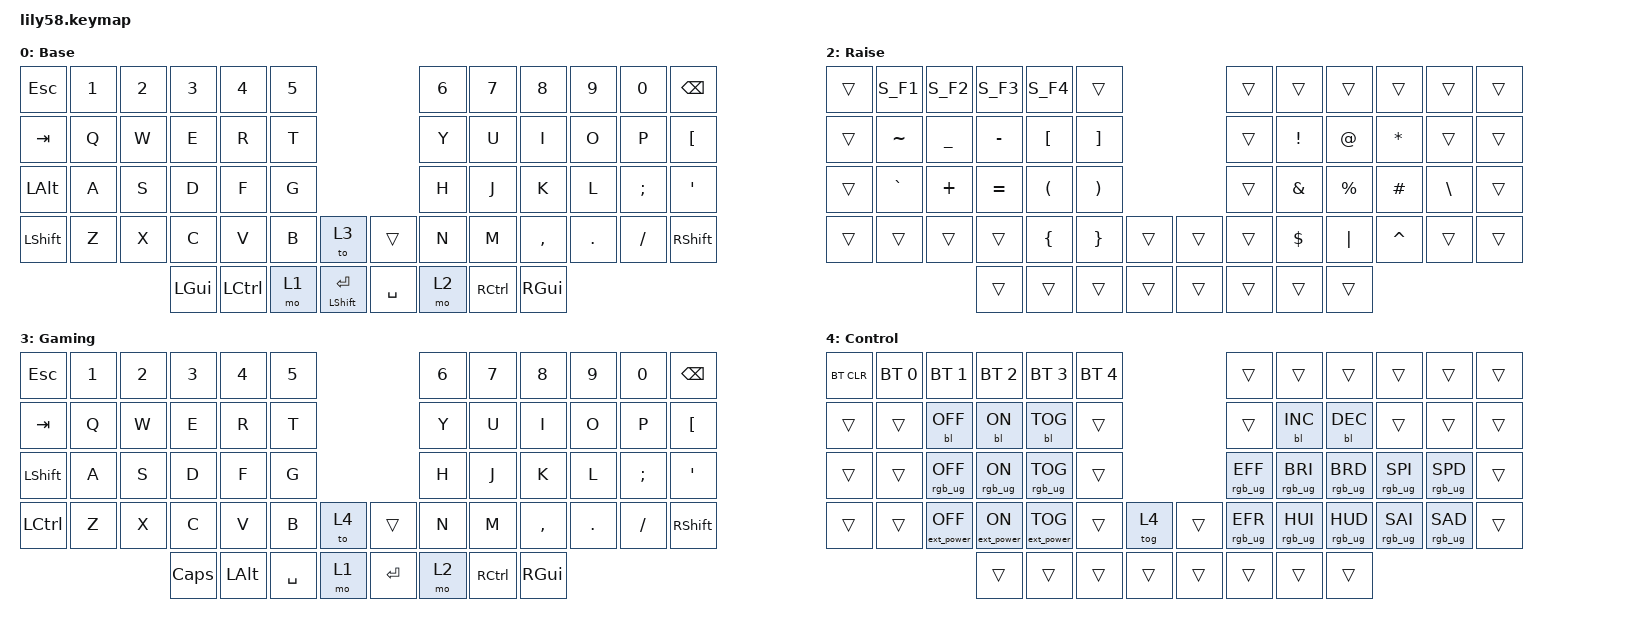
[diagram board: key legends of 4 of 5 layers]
/*
 * Copyright (c) 2020 The ZMK Contributors
 *
 * SPDX-License-Identifier: MIT
 */

#include <behaviors.dtsi>
#include <dt-bindings/zmk/backlight.h>
#include <dt-bindings/zmk/bt.h>
#include <dt-bindings/zmk/ext_power.h>
#include <dt-bindings/zmk/keys.h>
#include <dt-bindings/zmk/rgb.h>
#include <dt-bindings/led/led.h>

&led_strip {
    chain-length = <35>;
};

/ {
    macros {
        S_F1: S_F1 {
            compatible = "zmk,behavior-macro";
            #binding-cells = <0>;
            bindings = <&kt LSHFT &kp F1 &kt LSHFT>;
            label = "S_F1";
        };

        S_F2: S_F2 {
            compatible = "zmk,behavior-macro";
            #binding-cells = <0>;
            bindings = <&kt LSHFT &kp F2 &kt LSHFT>;
            label = "S_F2";
        };

        S_F3: S_F3 {
            compatible = "zmk,behavior-macro";
            #binding-cells = <0>;
            bindings = <&kt LSHFT &kp F3 &kt LSHFT>;
            label = "S_F3";
        };

        S_F4: S_F4 {
            compatible = "zmk,behavior-macro";
            #binding-cells = <0>;
            bindings = <&kt LSHFT &kp F4 &kt LSHFT>;
            label = "S_F4";
        };
    };

    keymap {
        compatible = "zmk,keymap";

        default_layer {
            display-name = "Base";

            // ---------------------------------------------------------------------------------------------------------------
            // |  ESC  |  1  |  2  |  3   |  4   |  5   |                      |  6   |  7    |  8    |  9   |   0   |  BACK |
            // |  TAB  |  Q  |  W  |  E   |  R   |  T   |                      |  Y   |  U    |  I    |  O   |   P   |   [   |
            // |  LALT |  A  |  S  |  D   |  F   |  G   |                      |  H   |  J    |  K    |  L   |   ;   |   '   |
            // | SHIFT |  Z  |  X  |  C   |  V   |  B   |  TOG_3  |  | POW_TOG |  N   |  M    |  ,    |  .   |   /   | SHIFT |
            //        | GUI  | CTRL  | BACK/LOWER |  ENTER/SHIFT  |  | SPACE   | ESC/RAISE | CTRL  | GUI   |

            bindings = <
&kp ESC    &kp N1  &kp N2  &kp N3    &kp N4     &kp N5                                   &kp N6   &kp N7     &kp N8     &kp N9   &kp N0    &kp BACKSPACE
&kp TAB    &kp Q   &kp W   &kp E     &kp R      &kp T                                    &kp Y    &kp U      &kp I      &kp O    &kp P     &kp LEFT_BRACKET
&kp LALT   &kp A   &kp S   &kp D     &kp F      &kp G                                    &kp H    &kp J      &kp K      &kp L    &kp SEMI  &kp SQT
&kp LSHFT  &kp Z   &kp X   &kp C     &kp V      &kp B     &to 3              &trans      &kp N    &kp M      &kp COMMA  &kp DOT  &kp FSLH  &kp RSHFT
                           &kp LGUI  &kp LCTRL  &mo 1     &mt LSHFT ENTER    &kp SPACE   &mo 2    &kp RCTRL  &kp RGUI
            >;
        };

        lower_layer {
            display-name = "Lower";

            // -----------------------------------------------------------------------------------------------------------------
            // |  F1   |  F2 | F3  |  F4 |  F5 |  F6  |                   |  F7  |  F8   |  F9   |  F10 |  F11  |   F12   |
            // |       |     |  7  |  8  |  9  |      |                   |      |  P_UP | P_DOWN|      | PRINT | NUMLOCk |
            // | CAPS  |     |  4  |  5  |  6  |  0   |                   |  <-  |   v   |   ^   |  ->  |       |         |
            // |       |     |  1  |  2  |  3  |      |        |  |       | DEL  |  HOME |  END  |      |       |         |
            //                           |     |      |        |  |       |      |       |       |      |

            bindings = <
&kp F1    &kp F2  &kp F3  &kp F4  &kp F5  &kp F6                           &kp F7      &kp F8         &kp F9        &kp F11          &kp F12
&trans    &trans  &kp N7  &kp N8  &kp N9  &trans                           &trans      &kp PAGE_DOWN  &kp PAGE_UP   &kp PRINTSCREEN  &kp KP_NUMLOCK
&kp CAPS  &trans  &kp N4  &kp N5  &kp N6  &kp N0                           &kp LEFT    &kp DOWN       &kp UP     T  &trans           &trans
&trans    &trans  &kp N1  &kp N2  &kp N3  &trans  &trans    &trans         &kp DELETE  &kp HOME       &kp trans  rans     &trans           &trans
                          &trans  &trans  &trans  &trans    &kp BACKSPACE  &kp ESC     &trans     
            >;
        };

        raise_layer {
            display-name = "Raise";

            // ------------------------------------------------------------------------------------------------------------
            // |       | S_F1 | S_F2 | S_F3 | S_F4 |      |                   |      |       |       |      |       |       |
            // |       |  ~   |  -   |  _   |  [   |  ]   |                   |      |   !   |   @   |  *   |       |       |
            // |       |  `   |  +   |  =   |  (   |  )   |                   |      |   &   |   %   |  #   |   \   |       |
            // |       |      |      |      |  {   |  }   |        |  |       |      |   $   |   |   |  ^   |       |       |
            //                       |      |      |      |        |  |       |      |       |       |

            bindings = <
&trans  &S_F1      &S_F2      &S_F3           &S_F4                 &trans                                   &trans  &trans         &trans       &trans        &trans         &trans
&trans  &kp TILDE  &kp UNDERSCORE  &kp MINUS  &kp LEFT_BRACKET      &kp RIGHT_BRACKET                        &trans  &kp EXCL       &kp AT_SIGN  &kp ASTERISK  &trans         &trans
&trans  &kp GRAVE  &kp PLUS   &kp EQUAL       &kp LEFT_PARENTHESIS  &kp RIGHT_PARENTHESIS                    &trans  &kp AMPERSAND  &kp PERCENT  &kp HASH      &kp BACKSLASH  &trans
&trans  &trans     &trans     &trans          &kp LEFT_BRACE        &kp RIGHT_BRACE        &trans    &trans  &trans  &kp DOLLAR     &kp PIPE     &kp CARET     &trans         &trans
                              &trans          &trans                &trans                 &trans    &trans  &trans  &trans         &trans
            >;
        };

        gaming_layer {
            display-name = "Gaming";

            // ----------------------------------------------------------------------------------------------------------------
            // |  ESC  |  1  |  2  |  3   |   4   |  5   |                       |  6   |  7    |  8    |  9   |   0   |  BKSP |
            // |  TAB  |  Q  |  W  |  E   |   R   |  T   |                       |  Y   |  U    |  I    |  O   |   P   |   [   |
            // | SHIFT |  A  |  S  |  D   |   F   |  G   |                       |  H   |  J    |  K    |  L   |   ;   |   '   |
            // | CTRL  |  Z  |  X  |  C   |   V   |  B   |  TOG_4 |  |  POW_TOG  |  N   |  M    |  ,    |  .   |   /   | SHIFT |
            //                     | CAPS |  ALT  | SPACE|  LOWER |  | ENTER | RAISE| BSPC  | GUI   |

            bindings = <
&kp ESC         &kp N1  &kp N2  &kp N3     &kp N4        &kp N5                        &kp N6  &kp N7     &kp N8     &kp N9   &kp N0    &kp BACKSPACE
&kp TAB         &kp Q   &kp W   &kp E      &kp R         &kp T                         &kp Y   &kp U      &kp I      &kp O    &kp P     &kp LEFT_BRACKET
&kp LEFT_SHIFT  &kp A   &kp S   &kp D      &kp F         &kp G                         &kp H   &kp J      &kp K      &kp L    &kp SEMI  &kp SQT
&kp LCTRL       &kp Z   &kp X   &kp C      &kp V         &kp B      &to 4     &trans   &kp N   &kp M      &kp COMMA  &kp DOT  &kp FSLH  &kp RSHFT
                                &kp CAPS   &kp LEFT_ALT  &kp SPACE  &mo 1     &kp RET  &mo 2   &kp RCTRL  &kp RGUI
            >;
        };

        keyboard_control_layer {
            display-name = "Control";

            // ---------------------------------------------------------------------------------------------------------------------------------------------------------
            // | BTCLR |  BT1  |  BT2    |   BT3  |   BT4   |  BT5 |                      |          |             |              |             |              |       |
            // |       |       | BL_OFF  | BL_ON  | BL_TOG  |      |                      |          | BL +        | BL -         |             |              |       |
            // |       |       | RGB_OFF | RGB_ON | RGB_TOG |      |                      | RGB_NEXT | RGB_BRIGHT+ | RGB_BRIGHT - | RGB_SPEED + |  RGB_SPEED - |       |
            // |       |       | EP_OFF  | EP_ON  | EP_TOG  |      |  TOG_0 |  |  POW_TOG | RGB_PREV | RGB_HUE +   | RGB_HUE -    | RGB_SAT +   | RGB_SAT -    |       |
            //                           |        |         |      |        |  |          |          |             |              |

            bindings = <
&bt BT_CLR  &bt BT_SEL 0  &bt BT_SEL 1       &bt BT_SEL 2      &bt BT_SEL 3       &bt BT_SEL 4                     &trans           &trans           &trans           &trans           &trans           &trans
&trans      &trans        &bl BL_OFF         &bl BL_ON         &bl BL_TOG         &trans                           &trans           &bl BL_INC       &bl BL_DEC       &trans           &trans           &trans
&trans      &trans        &rgb_ug RGB_OFF    &rgb_ug RGB_ON    &rgb_ug RGB_TOG    &trans                           &rgb_ug RGB_EFF  &rgb_ug RGB_BRI  &rgb_ug RGB_BRD  &rgb_ug RGB_SPI  &rgb_ug RGB_SPD  &trans
&trans      &trans        &ext_power EP_OFF  &ext_power EP_ON  &ext_power EP_TOG  &trans        &tog 4    &trans   &rgb_ug RGB_EFR  &rgb_ug RGB_HUI  &rgb_ug RGB_HUD  &rgb_ug RGB_SAI  &rgb_ug RGB_SAD  &trans
                                             &trans            &trans             &trans        &trans    &trans   &trans           &trans           &trans
            >;
        };
    };
};
